# STM32H7P5xx register map
File version: 1.0
Registers are 32-bit, read-write, reset 0x0 unless marked. A register's access mark holds for its fields unless they carry their own. Offsets are from the block's base; [hi:lo] are bit positions; {n}, {i} and the like mark numbered series; 'fields as' and 'values as' point back to an identical list.

## RNG — True random number generator (RNG)
Base 0x48020000
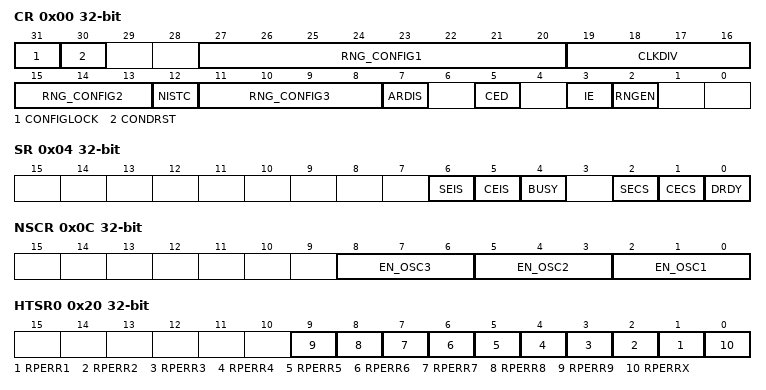
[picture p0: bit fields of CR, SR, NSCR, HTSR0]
0x00 CR — RNG control register
  [31] CONFIGLOCK, [30] CONDRST, [27:20] RNG_CONFIG1, [19:16] CLKDIV, [15:13] RNG_CONFIG2, [12] NISTC, [11:8] RNG_CONFIG3, [7] ARDIS, [5] CED, [3] IE, [2] RNGEN
0x04 SR — RNG status register
  [6] SEIS, [5] CEIS, [4] BUSY, [2] SECS, [1] CECS, [0] DRDY
0x08 DR ro — RNG data register
  [31:0] RNDATA — Random data
0x0C NSCR — RNG noise source control register
  [8:6] EN_OSC3 — Oscillator 1 input enable bits
  [5:3] EN_OSC2 — Oscillator 2 input enable bits
  [2:0] EN_OSC1 — Oscillator 1 input enable bits
{0x10+4i} HTCR{i} (i=0..3) — RNG health test configuration register
  [31:0] HTCFG
0x20 HTSR0 ro — RNG health test status register
  [n] RPERR{n} (n=1..9) — Repetitive error for oscillator i
  [0] RPERRX — Repetitive error after the XOR
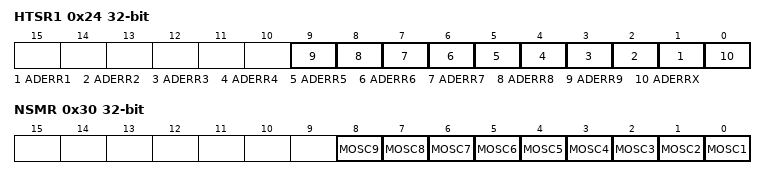
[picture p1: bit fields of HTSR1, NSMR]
0x24 HTSR1 ro — RNG health test status register
  [n] ADERR{n} (n=1..9) — Adaptative error for oscillator i
  [0] ADERRX — Adaptative error after the XOR
0x30 NSMR — RNG health test status register
  [n-1] MOSC{n} (n=1..9) — Mask oscillator i

## HASH — Hash processor
Base 0x48020400
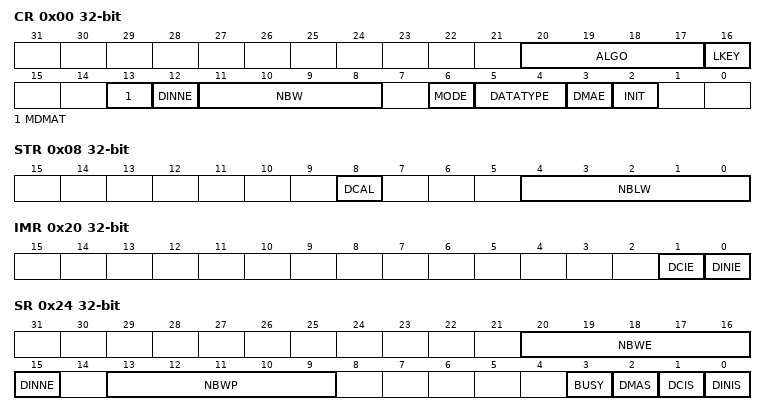
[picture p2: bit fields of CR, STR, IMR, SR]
0x00 CR — HASH control register
  [20:17] ALGO — Algorithm selection
  [16] LKEY — Long key selection
  [13] MDMAT — Multiple DMA transfers
  [12] DINNE — DIN not empty
  [11:8] NBW
  [6] MODE — Mode selection
  [5:4] DATATYPE — Data type selection
  [3] DMAE — DMA enable
  [2] INIT
0x04 DIN — HASH data input register
  [31:0] DATAIN — Data input
0x08 STR — HASH start register
  [8] DCAL — Digest calculation
  [4:0] NBLW
{0xC+4i} HRA{i} ro (i=0..4) — HASH digest registers
  [31:0] H — Hash data x
0x20 IMR — HASH interrupt enable register
  [1] DCIE
  [0] DINIE — Data input interrupt enable
0x24 SR — HASH status register
  [20:16] NBWE — Number of words expected
  [15] DINNE — DIN not empty
  [13:9] NBWP
  [3] BUSY — Busy bit
  [2] DMAS — DMA Status
  [1] DCIS
  [0] DINIS — Data input interrupt status
{0xF8+4i} CSR{i} (i=0..102) — HASH context swap registers
  [31:0] CS — Context swap x
{0x310+4i} HR{i} ro (i=0..15) — HASH digest registers
  [31:0] H — Hash data x

## ADC12_COMMON
Base 0x48026300
Same registers: ADC34_COMMON 0x48026700
0x00 CSR ro — ADC common status register
0x08 CCR — ADC common control register
0x0C CDR ro — ADC common regular data register for dual mode
0x10 CDR2 ro — ADC common regular data register for dual mode

## FMC_NORSRAM1
Base 0x52004000
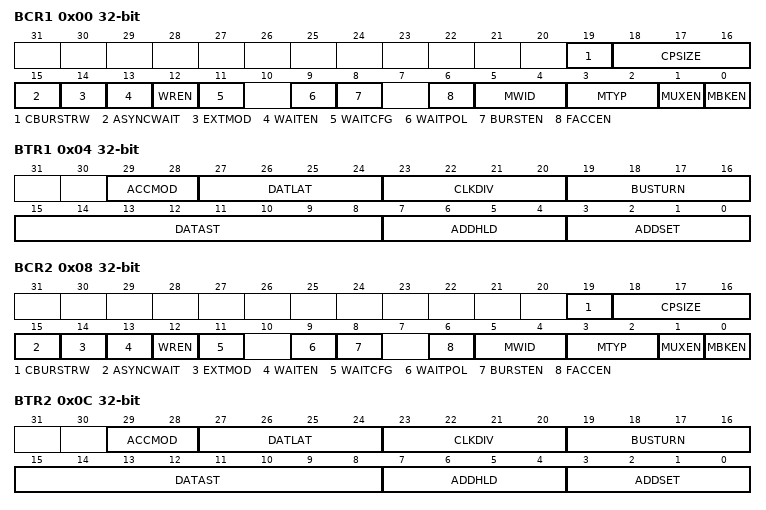
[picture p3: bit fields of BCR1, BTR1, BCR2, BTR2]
0x00 BCR1 — NOR/SRAM chip-select control register
  [19] CBURSTRW — Write burst enable
  [18:16] CPSIZE — CRAM page size
  [15] ASYNCWAIT
  [14] EXTMOD — Extended mode enable
  [13] WAITEN — Wait enable bit
  [12] WREN — Write enable bit
  [11] WAITCFG — Wait timing configuration
  [9] WAITPOL — Wait signal polarity bit
  [8] BURSTEN — Burst enable bit
  [6] FACCEN — Flash access enable
  [5:4] MWID — Memory data bus width
  [3:2] MTYP — Memory type
  [1] MUXEN
  [0] MBKEN — Memory bank enable bit
0x04 BTR1 — NOR/SRAM chip-select timing register
  [29:28] ACCMOD — Access mode
  [27:24] DATLAT
  [23:20] CLKDIV — Clock divide ratio
  [19:16] BUSTURN — Bus turnaround phase duration
  [15:8] DATAST — Data-phase duration
  [7:4] ADDHLD — Address-hold phase duration
  [3:0] ADDSET — Address setup phase duration
0x08 BCR2 — NOR/SRAM chip-select control register
  fields as BCR1
0x0C BTR2 — NOR/SRAM chip-select timing register
  fields as BTR1
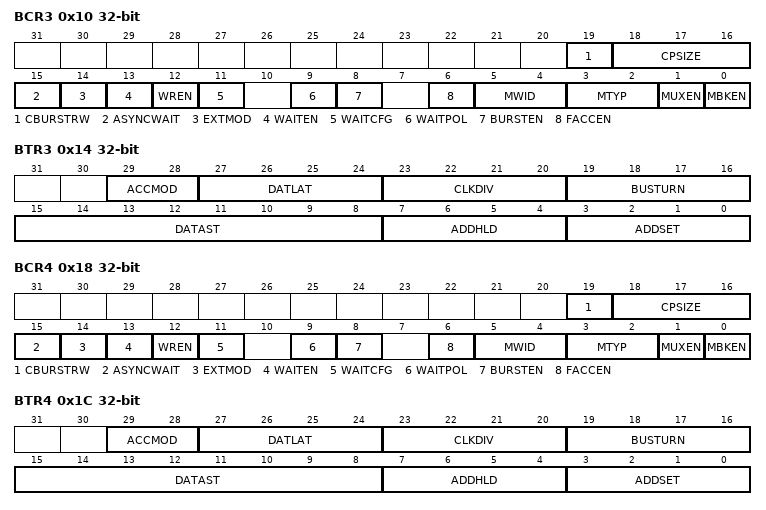
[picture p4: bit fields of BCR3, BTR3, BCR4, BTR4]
0x10 BCR3 — NOR/SRAM chip-select control register
  fields as BCR1
0x14 BTR3 — NOR/SRAM chip-select timing register
  fields as BTR1
0x18 BCR4 — NOR/SRAM chip-select control register
  fields as BCR1
0x1C BTR4 — NOR/SRAM chip-select timing register
  fields as BTR1
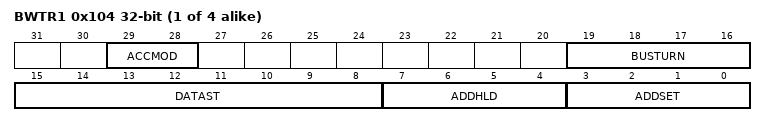
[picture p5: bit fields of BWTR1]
{0xFC+8i} BWTR{i} (i=1..4) — NOR/SRAM write timing registers
  [29:28] ACCMOD — Access mode
  [19:16] BUSTURN — Bus turnaround phase duration
  [15:8] DATAST — Data-phase duration
  [7:4] ADDHLD — Address-hold phase duration
  [3:0] ADDSET — Address setup phase duration
